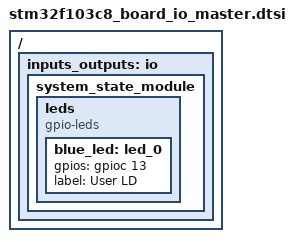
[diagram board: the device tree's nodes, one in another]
/*
 *	Author: Mohd Ramza <mohdramza@yahoo.com>
 *	SPDX-License-Identifier: Apache-2.0
 *	list of the IO used in skycar
 */
/ {
	inputs_outputs:io {
		/* System state module */
		system_state_module {
			leds {
				compatible = "gpio-leds";
				blue_led: led_0 {
					gpios = <&gpioc 13 GPIO_ACTIVE_HIGH>;
					label = "User LD";
				};
			};
		};
	};
};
